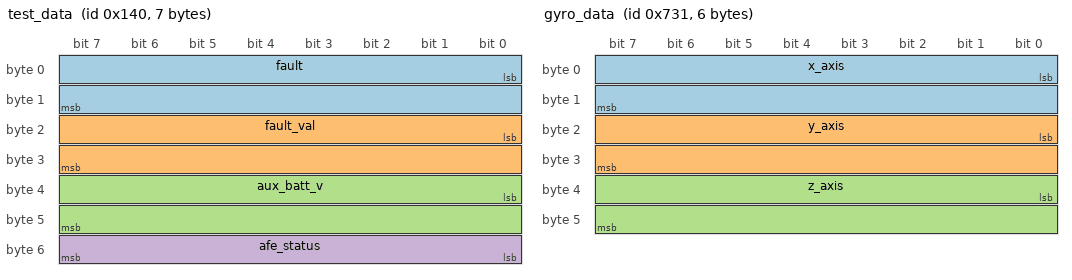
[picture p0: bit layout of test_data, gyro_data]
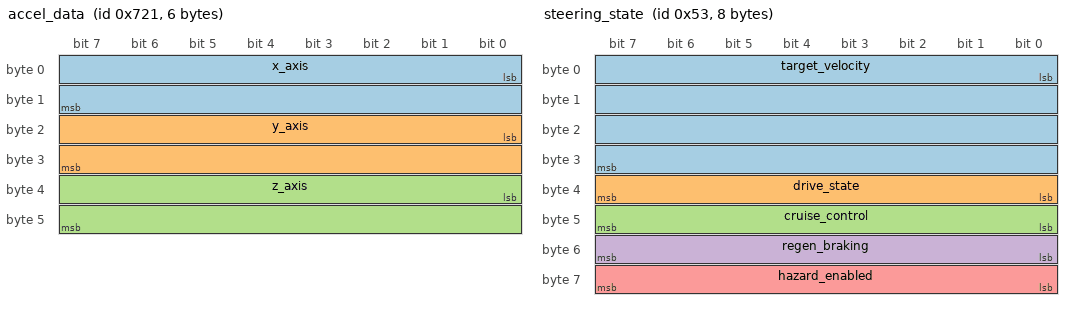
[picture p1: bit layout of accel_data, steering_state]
NS_ :

BS_:

BU_: REAR_CONTROLLER IMU CAN_COMMUNICATION STEERING TELEMETRY FRONT_CONTROLLER

BO_  320  test_data: 7 rear_controller
  SG_ fault : 0|16@1+ (1,0) [0|65535] "" power_distribution
  SG_ fault_val : 16|16@1+ (1,0) [0|65535] "" power_distribution
  SG_ aux_batt_v : 32|16@1+ (1,0) [0|65535] "" power_distribution
  SG_ afe_status : 48|8@1+ (1,0) [0|255] "" power_distribution

BO_   1841 gyro_data: 6 imu
  SG_ x_axis : 0|16@1+ (1,0) [0|65535] "" telemetry
  SG_ y_axis : 16|16@1+ (1,0) [0|65535] "" telemetry
  SG_ z_axis : 32|16@1+ (1,0) [0|65535] "" telemetry

BO_   1825 accel_data: 6 imu
  SG_ x_axis : 0|16@1+ (1,0) [0|65535] "" telemetry
  SG_ y_axis : 16|16@1+ (1,0) [0|65535] "" telemetry
  SG_ z_axis : 32|16@1+ (1,0) [0|65535] "" telemetry

BO_   1906 fast_one_shot_msg: 4 can_communication
  SG_ sig1 : 0|16@1+ (1,0) [0|65535] "" can_communication
  SG_ sig2 : 16|16@1+ (1,0) [0|65535] "" can_communication

BO_   1890 medium_one_shot_msg: 4 can_communication
  SG_ sig1 : 0|16@1+ (1,0) [0|65535] "" can_communication
  SG_ sig2 : 16|16@1+ (1,0) [0|65535] "" can_communication

BO_   1874 slow_one_shot_msg: 4 can_communication
  SG_ sig1 : 0|16@1+ (1,0) [0|65535] "" can_communication
  SG_ sig2 : 16|16@1+ (1,0) [0|65535] "" can_communication

BO_  83  steering_state: 8 steering
  SG_ target_velocity : 0|32@1+ (1,0) [0|4294967295] "" telemetry, bms_carrier
  SG_ drive_state : 32|8@1+ (1,0) [0|255] "" telemetry, bms_carrier
  SG_ cruise_control : 40|8@1+ (1,0) [0|255] "" telemetry, bms_carrier
  SG_ regen_braking : 48|8@1+ (1,0) [0|255] "" telemetry, bms_carrier
  SG_ hazard_enabled : 56|8@1+ (1,0) [0|255] "" telemetry, bms_carrier

BO_   1860 telemetry: 8 telemetry
  SG_ telemetry_data : 0|64@1+ (1,0) [0|18446744073709551615] "" telemetry

BO_   1365 front_controller_pedal_data: 5 front_controller
  SG_ percentage : 0|32@1+ (1,0) [0|4294967295] "" telemetry, bms_carrier
  SG_ brake_enabled : 32|8@1+ (1,0) [0|255] "" telemetry, bms_carrier
